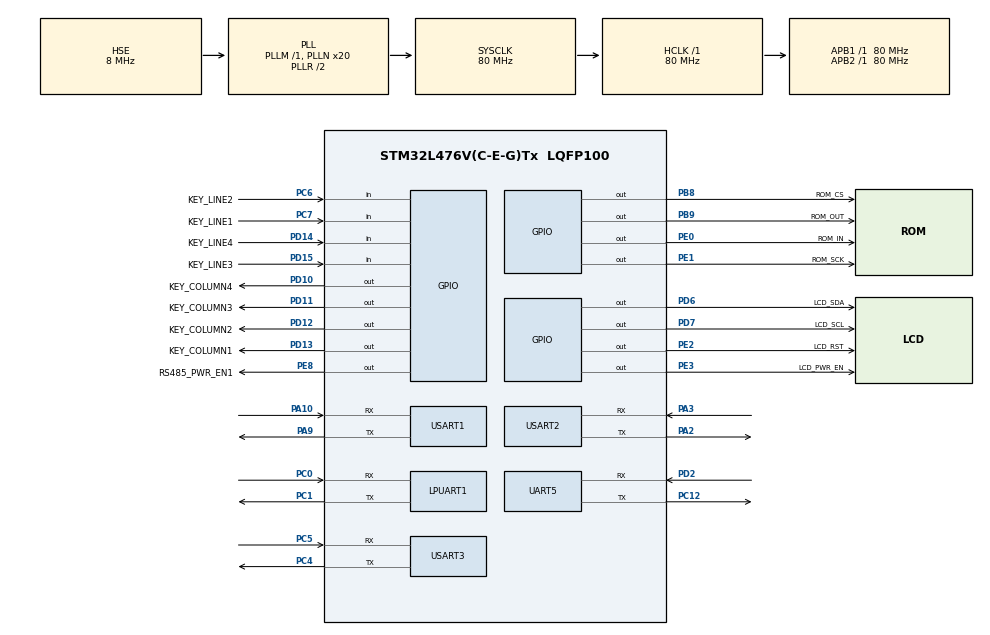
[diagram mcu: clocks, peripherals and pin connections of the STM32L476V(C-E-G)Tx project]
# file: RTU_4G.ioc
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Mcu.Family=STM32L4
Mcu.Name=STM32L476V(C-E-G)Tx
Mcu.Package=LQFP100
NVIC.PriorityGroup=NVIC_PRIORITYGROUP_2
NVIC.TIM1_BRK_TIM15_IRQn=true\:0\:0\:false\:false\:true\:true
NVIC.TIM2_IRQn=true\:0\:3\:true\:false\:true\:true
NVIC.USART1_IRQn=true\:0\:0\:false\:false\:true\:true
PA10.Mode=Asynchronous
PA10.Signal=USART1_RX
PA13\ (JTMS-SWDIO).Mode=Serial_Wire
PA13\ (JTMS-SWDIO).Signal=SYS_JTMS-SWDIO
PA14\ (JTCK-SWCLK).Mode=Serial_Wire
PA14\ (JTCK-SWCLK).Signal=SYS_JTCK-SWCLK
PA2.Mode=Asynchronous
PA2.Signal=USART2_TX
PA3.Mode=Asynchronous
PA3.Signal=USART2_RX
PA9.Mode=Asynchronous
PA9.Signal=USART1_TX
PB8.GPIO_Label=ROM_CS
PB8.GPIO_PuPd=GPIO_PULLUP
PB8.GPIO_Speed=GPIO_SPEED_FREQ_HIGH
PB8.Signal=GPIO_Output
PB9.GPIO_Label=ROM_OUT
PB9.GPIO_PuPd=GPIO_PULLUP
PB9.GPIO_Speed=GPIO_SPEED_FREQ_HIGH
PB9.Signal=GPIO_Output
PC0.Mode=Asynchronous
PC0.Signal=LPUART1_RX
PC1.Mode=Asynchronous
PC1.Signal=LPUART1_TX
PC12.Mode=Asynchronous
PC12.Signal=UART5_TX
PC14-OSC32_IN\ (PC14).Mode=LSE-External-Oscillator
PC14-OSC32_IN\ (PC14).Signal=RCC_OSC32_IN
PC15-OSC32_OUT\ (PC15).Mode=LSE-External-Oscillator
PC15-OSC32_OUT\ (PC15).Signal=RCC_OSC32_OUT
PC4.Mode=Asynchronous
PC4.Signal=USART3_TX
PC5.Mode=Asynchronous
PC5.Signal=USART3_RX
PC6.GPIO_Label=KEY_LINE2
PC6.GPIO_PuPd=GPIO_PULLUP
PC6.Signal=GPIO_Input
PC7.GPIO_Label=KEY_LINE1
PC7.GPIO_PuPd=GPIO_PULLUP
PC7.Signal=GPIO_Input
PD10.GPIO_Label=KEY_COLUMN4
PD10.GPIO_ModeDefaultOutputPP=GPIO_MODE_OUTPUT_OD
PD10.GPIO_PuPd=GPIO_PULLDOWN
PD10.GPIO_Speed=GPIO_SPEED_FREQ_MEDIUM
PD10.PinState=GPIO_PIN_RESET
PD10.Signal=GPIO_Output
PD11.GPIO_Label=KEY_COLUMN3
PD11.GPIO_ModeDefaultOutputPP=GPIO_MODE_OUTPUT_OD
PD11.GPIO_PuPd=GPIO_PULLDOWN
PD11.GPIO_Speed=GPIO_SPEED_FREQ_MEDIUM
PD11.PinState=GPIO_PIN_RESET
PD11.Signal=GPIO_Output
PD12.GPIO_Label=KEY_COLUMN2
PD12.GPIO_ModeDefaultOutputPP=GPIO_MODE_OUTPUT_OD
PD12.GPIO_PuPd=GPIO_PULLDOWN
PD12.GPIO_Speed=GPIO_SPEED_FREQ_MEDIUM
PD12.PinState=GPIO_PIN_RESET
PD12.Signal=GPIO_Output
PD13.GPIO_Label=KEY_COLUMN1
PD13.GPIO_ModeDefaultOutputPP=GPIO_MODE_OUTPUT_OD
PD13.GPIO_PuPd=GPIO_PULLDOWN
PD13.GPIO_Speed=GPIO_SPEED_FREQ_MEDIUM
PD13.PinState=GPIO_PIN_RESET
PD13.Signal=GPIO_Output
PD14.GPIO_Label=KEY_LINE4
PD14.GPIO_PuPd=GPIO_PULLUP
PD14.Signal=GPIO_Input
PD15.GPIO_Label=KEY_LINE3
PD15.GPIO_PuPd=GPIO_PULLUP
PD15.Signal=GPIO_Input
PD2.Mode=Asynchronous
PD2.Signal=UART5_RX
PD6.GPIO_Label=LCD_SDA
PD6.GPIO_ModeDefaultOutputPP=GPIO_MODE_OUTPUT_PP
PD6.GPIO_PuPd=GPIO_PULLUP
PD6.GPIO_Speed=GPIO_SPEED_FREQ_HIGH
PD6.Signal=GPIO_Output
PD7.GPIO_Label=LCD_SCL
PD7.GPIO_PuPd=GPIO_PULLUP
PD7.GPIO_Speed=GPIO_SPEED_FREQ_HIGH
PD7.PinState=GPIO_PIN_RESET
PD7.Signal=GPIO_Output
PE0.GPIO_Label=ROM_IN
PE0.GPIO_ModeDefaultOutputPP=GPIO_MODE_OUTPUT_PP
PE0.GPIO_PuPd=GPIO_PULLUP
PE0.GPIO_Speed=GPIO_SPEED_FREQ_HIGH
PE0.Signal=GPIO_Output
PE1.GPIO_Label=ROM_SCK
PE1.GPIO_PuPd=GPIO_PULLUP
PE1.GPIO_Speed=GPIO_SPEED_FREQ_HIGH
PE1.Signal=GPIO_Output
PE2.GPIO_Label=LCD_RST
PE2.GPIO_PuPd=GPIO_PULLUP
PE2.Signal=GPIO_Output
PE3.GPIO_Label=LCD_PWR_EN
PE3.GPIO_PuPd=GPIO_PULLUP
PE3.Signal=GPIO_Output
PE8.GPIO_Label=RS485_PWR_EN1
PE8.GPIO_PuPd=GPIO_PULLUP
PE8.Signal=GPIO_Output
PH0-OSC_IN\ (PH0).Mode=HSE-External-Oscillator
PH0-OSC_IN\ (PH0).Signal=RCC_OSC_IN
PH1-OSC_OUT\ (PH1).Mode=HSE-External-Oscillator
PH1-OSC_OUT\ (PH1).Signal=RCC_OSC_OUT
ProjectManager.HeapSize=0x200
ProjectManager.StackSize=0x400
ProjectManager.TargetToolchain=MDK-ARM V5
RCC.ADCFreq_Value=32000000
RCC.AHBFreq_Value=80000000
RCC.APB1Freq_Value=80000000
RCC.APB1TimFreq_Value=80000000
RCC.APB2Freq_Value=80000000
RCC.APB2TimFreq_Value=80000000
RCC.CortexFreq_Value=80000000
RCC.HCLKFreq_Value=80000000
RCC.HSE_VALUE=8000000
RCC.HSI_VALUE=16000000
RCC.MSIClockRange=RCC_MSIRANGE_11
RCC.MSI_VALUE=48000000
RCC.PLLN=20
RCC.PLLSourceVirtual=RCC_PLLSOURCE_HSE
RCC.SYSCLKFreq_VALUE=80000000
RCC.SYSCLKSource=RCC_SYSCLKSOURCE_PLLCLK
RCC.USBFreq_Value=32000000
RCC.VCOOutputFreq_Value=160000000
TIM1.AutoReloadPreload=TIM_AUTORELOAD_PRELOAD_ENABLE
TIM1.ClockDivision=TIM_CLOCKDIVISION_DIV4
TIM1.Period=10-1
TIM1.Prescaler=2000-1
TIM2.AutoReloadPreload=TIM_AUTORELOAD_PRELOAD_ENABLE
TIM2.ClockDivision=TIM_CLOCKDIVISION_DIV1
TIM2.Period=1000-1
TIM2.Prescaler=80-1
USART1.VirtualMode-Asynchronous=VM_ASYNC
USART2.VirtualMode-Asynchronous=VM_ASYNC
USART3.VirtualMode-Asynchronous=VM_ASYNC
VP_TIM1_VS_ClockSourceINT.Mode=Internal
VP_TIM2_VS_ClockSourceINT.Mode=Internal
board=custom

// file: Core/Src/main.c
/**
  ******************************************************************************
  * @file           : main.c
  * @brief          : Main program body
  ******************************************************************************
  ** This notice applies to any and all portions of this file
  * that are not between comment pairs USER CODE BEGIN and
  * USER CODE END. Other portions of this file, whether
  * inserted by the user or by software development tools
  * are owned by their respective copyright owners.
  *
  * COPYRIGHT(c) 2018 STMicroelectronics
  *
  * Redistribution and use in source and binary forms, with or without modification,
  * are permitted provided that the following conditions are met:
  *   1. Redistributions of source code must retain the above copyright notice,
  *      this list of conditions and the following disclaimer.
  *   2. Redistributions in binary form must reproduce the above copyright notice,
  *      this list of conditions and the following disclaimer in the documentation
  *      and/or other materials provided with the distribution.
  *   3. Neither the name of STMicroelectronics nor the names of its contributors
  *      may be used to endorse or promote products derived from this software
  *      without specific prior written permission.
  *
  * THIS SOFTWARE IS PROVIDED BY THE COPYRIGHT HOLDERS AND CONTRIBUTORS "AS IS"
  * AND ANY EXPRESS OR IMPLIED WARRANTIES, INCLUDING, BUT NOT LIMITED TO, THE
  * IMPLIED WARRANTIES OF MERCHANTABILITY AND FITNESS FOR A PARTICULAR PURPOSE ARE
  * DISCLAIMED. IN NO EVENT SHALL THE COPYRIGHT HOLDER OR CONTRIBUTORS BE LIABLE
  * FOR ANY DIRECT, INDIRECT, INCIDENTAL, SPECIAL, EXEMPLARY, OR CONSEQUENTIAL
  * DAMAGES (INCLUDING, BUT NOT LIMITED TO, PROCUREMENT OF SUBSTITUTE GOODS OR
  * SERVICES; LOSS OF USE, DATA, OR PROFITS; OR BUSINESS INTERRUPTION) HOWEVER
  * CAUSED AND ON ANY THEORY OF LIABILITY, WHETHER IN CONTRACT, STRICT LIABILITY,
  * OR TORT (INCLUDING NEGLIGENCE OR OTHERWISE) ARISING IN ANY WAY OUT OF THE USE
  * OF THIS SOFTWARE, EVEN IF ADVISED OF THE POSSIBILITY OF SUCH DAMAGE.
  *
  ******************************************************************************
  */
#include "main.h"
#include "stm32l4xx_hal.h"
#include "usart.h"
#include "tim.h"
#include "gpio.h"

/* USER CODE BEGIN Includes */
#include "Inc/key.h"
#include "PrivateTimer/PrivateTimer.h"
#include "PrivateList/PrivateList.h"
#include "Inc/LcdDriver.h"
#include "Application/GUI/gui.h"

/* USER CODE END Includes */

/* USER CODE BEGIN PV */
/* Private variables ---------------------------------------------------------*/

/* USER CODE END PV */

void SystemClock_Config(void);

/* USER CODE BEGIN PFP */
/* Private function prototypes -----------------------------------------------*/

/* USER CODE END PFP */

int main(void)
{

  /* MCU Configuration----------------------------------------------------------*/

  /* Reset of all peripherals, Initializes the Flash interface and the Systick. */
  HAL_Init();

  /* USER CODE BEGIN Init */
	uint32_t test_count=0;
  /* USER CODE END Init */

  /* Configure the system clock */
  SystemClock_Config();

  /* Initialize all configured peripherals */
  MX_GPIO_Init();
  MX_TIM1_Init();
  MX_TIM2_Init();
  MX_USART2_UART_Init();
  MX_USART3_UART_Init();
  MX_LPUART1_UART_Init();
  MX_USART1_UART_Init();
  MX_UART5_Init();
  /* USER CODE BEGIN 2 */

	CUSTOM_TimerInit(0,0);
	KEY_Init();
	LCD_Init();
	APP_GUI_Init();
	HAL_TIM_Base_Start_IT(&htim2);
  /* USER CODE END 2 */

  /* Infinite loop */
  while (1)
  {

  /* USER CODE BEGIN 3 */
	  MsgPut(MSG_HOUR_RAIN,(void*)test_count,sizeof(uint32_t));
	  HAL_Delay(1000);
	  test_count++;
  }
  /* USER CODE END 3 */

}

void SystemClock_Config(void)
{

  RCC_OscInitTypeDef RCC_OscInitStruct;
  RCC_ClkInitTypeDef RCC_ClkInitStruct;
  RCC_PeriphCLKInitTypeDef PeriphClkInit;

    /**Initializes the CPU, AHB and APB busses clocks
    */
  RCC_OscInitStruct.OscillatorType = RCC_OSCILLATORTYPE_HSE;
  RCC_OscInitStruct.HSEState = RCC_HSE_ON;
  RCC_OscInitStruct.PLL.PLLState = RCC_PLL_ON;
  RCC_OscInitStruct.PLL.PLLSource = RCC_PLLSOURCE_HSE;
  RCC_OscInitStruct.PLL.PLLM = 1;
  RCC_OscInitStruct.PLL.PLLN = 20;
  RCC_OscInitStruct.PLL.PLLP = RCC_PLLP_DIV7;
  RCC_OscInitStruct.PLL.PLLQ = RCC_PLLQ_DIV2;
  RCC_OscInitStruct.PLL.PLLR = RCC_PLLR_DIV2;
  if (HAL_RCC_OscConfig(&RCC_OscInitStruct) != HAL_OK)
  {
    _Error_Handler(__FILE__, __LINE__);
  }

    /**Initializes the CPU, AHB and APB busses clocks
    */
  RCC_ClkInitStruct.ClockType = RCC_CLOCKTYPE_HCLK|RCC_CLOCKTYPE_SYSCLK
                              |RCC_CLOCKTYPE_PCLK1|RCC_CLOCKTYPE_PCLK2;
  RCC_ClkInitStruct.SYSCLKSource = RCC_SYSCLKSOURCE_PLLCLK;
  RCC_ClkInitStruct.AHBCLKDivider = RCC_SYSCLK_DIV1;
  RCC_ClkInitStruct.APB1CLKDivider = RCC_HCLK_DIV1;
  RCC_ClkInitStruct.APB2CLKDivider = RCC_HCLK_DIV1;

  if (HAL_RCC_ClockConfig(&RCC_ClkInitStruct, FLASH_LATENCY_4) != HAL_OK)
  {
    _Error_Handler(__FILE__, __LINE__);
  }

  PeriphClkInit.PeriphClockSelection = RCC_PERIPHCLK_USART1|RCC_PERIPHCLK_USART2
                              |RCC_PERIPHCLK_USART3|RCC_PERIPHCLK_UART5
                              |RCC_PERIPHCLK_LPUART1;
  PeriphClkInit.Usart1ClockSelection = RCC_USART1CLKSOURCE_PCLK2;
  PeriphClkInit.Usart2ClockSelection = RCC_USART2CLKSOURCE_PCLK1;
  PeriphClkInit.Usart3ClockSelection = RCC_USART3CLKSOURCE_PCLK1;
  PeriphClkInit.Uart5ClockSelection = RCC_UART5CLKSOURCE_PCLK1;
  PeriphClkInit.Lpuart1ClockSelection = RCC_LPUART1CLKSOURCE_PCLK1;
  if (HAL_RCCEx_PeriphCLKConfig(&PeriphClkInit) != HAL_OK)
  {
    _Error_Handler(__FILE__, __LINE__);
  }

    /**Configure the main internal regulator output voltage
    */
  if (HAL_PWREx_ControlVoltageScaling(PWR_REGULATOR_VOLTAGE_SCALE1) != HAL_OK)
  {
    _Error_Handler(__FILE__, __LINE__);
  }

    /**Configure the Systick interrupt time
    */
  HAL_SYSTICK_Config(HAL_RCC_GetHCLKFreq()/1000);

    /**Configure the Systick
    */
  HAL_SYSTICK_CLKSourceConfig(SYSTICK_CLKSOURCE_HCLK);

  /* SysTick_IRQn interrupt configuration */
  HAL_NVIC_SetPriority(SysTick_IRQn, 0, 0);
}

void _Error_Handler(char *file, int line)
{
  while(1)
  {
  }
}

/************************ (C) COPYRIGHT STMicroelectronics *****END OF FILE****/
